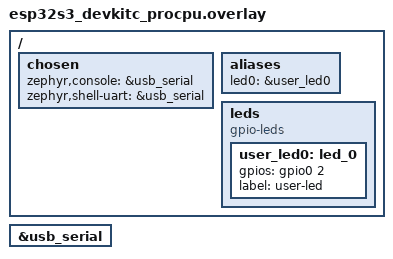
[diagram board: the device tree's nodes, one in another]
#include <zephyr/dt-bindings/gpio/gpio.h>

/ {
	chosen {
		zephyr,console = &usb_serial;
		zephyr,shell-uart = &usb_serial;
	};

	aliases {
		led0 = &user_led0;
	};

	leds {
		compatible = "gpio-leds";
		user_led0: led_0 {
			gpios = <&gpio0 2 GPIO_ACTIVE_HIGH>;
			label = "user-led";
		};
	};
};

&usb_serial {
	status = "okay";
};
